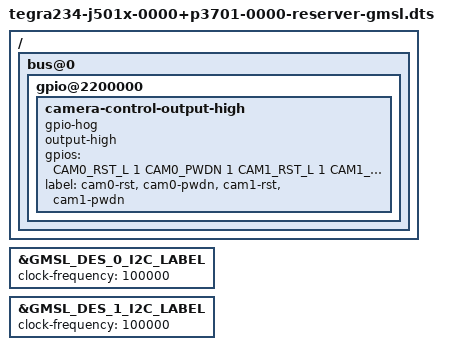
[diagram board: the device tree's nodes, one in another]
// SPDX-License-Identifier: GPL-2.0-only
// SPDX-FileCopyrightText: Copyright (c) 2023, NVIDIA CORPORATION & AFFILIATES.  All rights reserved.

/dts-v1/;


#include "tegra234-j501x-0000+p3701-0000-reserver.dts"
#define CAM0_RST_L	TEGRA234_MAIN_GPIO(H, 3)
#define CAM0_PWDN	TEGRA234_MAIN_GPIO(H, 6)
#define CAM1_RST_L	TEGRA234_MAIN_GPIO(AC, 1)
#define CAM1_PWDN	TEGRA234_MAIN_GPIO(AC, 0)

/ {
	bus@0 {
		/* set camera gpio direction to output */
		gpio@2200000 {
			camera-control-output-high {
				gpio-hog;
				output-high;
				gpios = <CAM0_RST_L 1 CAM0_PWDN 1
						CAM1_RST_L 1 CAM1_PWDN 1>;
				label = "cam0-rst", "cam0-pwdn",
					"cam1-rst", "cam1-pwdn";
			};
		};
	};
};

#define GMSL

#define GMSL_TEGRA_PORT                        0

#define GMSL_DES_PHY                   1
#define GMSL_DES_PHY_NUM_LANES         4

// #define GMSL_TEGRA_PORT                     1
// #define GMSL_DES_PHY                        0
// #define GMSL_DES_PHY_NUM_LANES              2 
#define GMSL_DES_PHY_LINK_FREQ         1250000000
//#define GMSL_DES_PHY_LINK_FREQ               750000000

#define GMSL_CAMERA_NUM                        8
#define GMSL_DES_MAX96724
// #define GMSL_SER_0_MAX9295A
#define GMSL_SER_0_MAX96717
#define GMSL_SER_1_MAX96717
#define GMSL_SER_2_MAX96717
#define GMSL_SER_3_MAX96717
#define GMSL_SER_4_MAX96717
#define GMSL_SER_5_MAX96717
#define GMSL_SER_6_MAX96717
#define GMSL_SER_7_MAX96717


#define GMSL_CAM_0_TEGRA_OX03A
#define GMSL_CAM_1_TEGRA_OX03A
#define GMSL_CAM_2_TEGRA_OX03A
#define GMSL_CAM_3_TEGRA_OX03A
#define GMSL_CAM_4_TEGRA_OX03A
#define GMSL_CAM_5_TEGRA_OX03A
#define GMSL_CAM_6_TEGRA_OX03A
#define GMSL_CAM_7_TEGRA_OX03A


#define GMSL_CAM_0_DEFAULT_HEX_ADDR    0x1a
#define GMSL_CAM_1_DEFAULT_HEX_ADDR    0x1a
#define GMSL_CAM_2_DEFAULT_HEX_ADDR    0x1a
#define GMSL_CAM_3_DEFAULT_HEX_ADDR    0x1a
#define GMSL_CAM_4_DEFAULT_HEX_ADDR    0x1a
#define GMSL_CAM_5_DEFAULT_HEX_ADDR    0x1a
#define GMSL_CAM_6_DEFAULT_HEX_ADDR    0x1a
#define GMSL_CAM_7_DEFAULT_HEX_ADDR    0x1a

#define GMSL_TEGRA_PLATFORM

// #if GMSL_TEGRA_PORT == 0 || GMSL_TEGRA_PORT == 1
// #define GMSL_DES_I2C_LABEL cam_i2c_0
// #elif GMSL_TEGRA_PORT == 2 || GMSL_TEGRA_PORT == 3
// #define GMSL_DES_I2C_LABEL cam_i2c_1

#define GMSL_DES_0_I2C_LABEL  dp_aux_ch1_i2c
#define GMSL_DES_1_I2C_LABEL  hdr40_i2c1


#if GMSL_TEGRA_PORT == 1
#define GMSL_TEGRA_LANE_POLARITY_SWAP
#endif

&GMSL_DES_0_I2C_LABEL {
    clock-frequency = <100000>;
};

&GMSL_DES_1_I2C_LABEL {
	clock-frequency = <100000>;
};

#include "gmsl/gmsl.dtsi"
